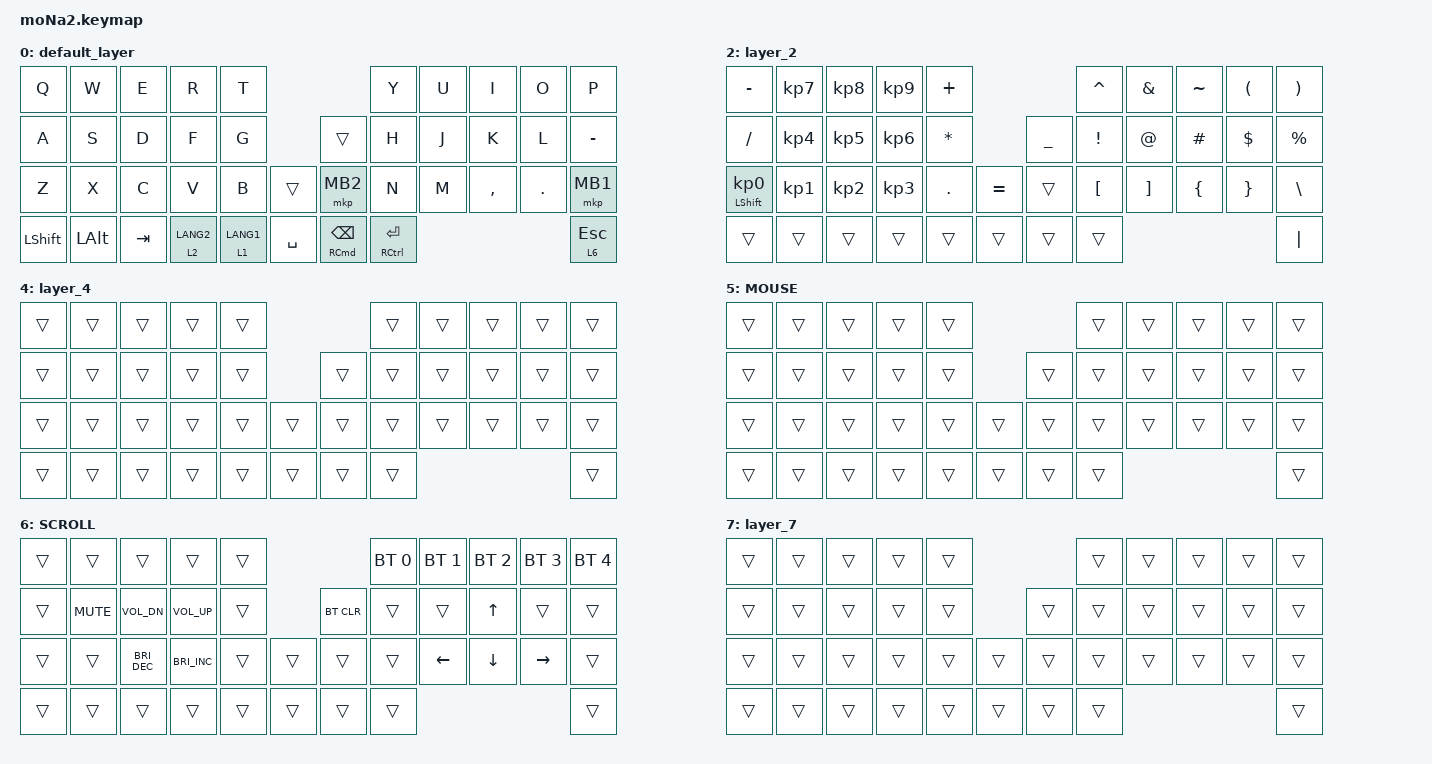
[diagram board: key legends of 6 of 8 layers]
#include <behaviors.dtsi>
#include <dt-bindings/zmk/bt.h>
#include <dt-bindings/zmk/keys.h>
#include <dt-bindings/zmk/pointing.h>

#define ZMK_POINTING_DEFAULT_SCRL_VAL 100
#define MOUSE 5
#define SCROLL 6

&mt {
    flavor = "balanced";
    quick-tap-ms = <0>;
};

/ {
    combos {
        compatible = "zmk,combos";

        combo_right_click {
            bindings = <&mkp MB2>;
            key-positions = <32 41>;
        };
    };

    macros {
        to_layer_0: to_layer_0 {
            compatible = "zmk,behavior-macro-one-param";
            #binding-cells = <1>;
            bindings = <&to 0 &macro_param_1to1 &kp MACRO_PLACEHOLDER>;
            label = "TO_LAYER_0";
        };

    };

    behaviors {
        lt_to_layer_0: lt_to_layer_0 {
            compatible = "zmk,behavior-hold-tap";
            label = "LAYER_TAP_TO_0";
            bindings = <&mo>, <&to_layer_0>;

            #binding-cells = <2>;
            tapping-term-ms = <200>;
        };

        /* [変更点1] スクロール方向を反転 */

        scroll_up_down: scroll_up_down {
            compatible = "zmk,behavior-sensor-rotate";
            #sensor-binding-cells = <0>;
            bindings = <&msc SCRL_UP>, <&msc SCRL_DOWN>;

            tap-ms = <20>;
            label = "scroll_up_down";
        };

        volume: volume {
            compatible = "zmk,behavior-sensor-rotate";
            label = "VOLUME";
            #sensor-binding-cells = <0>;
            bindings = <&kp C_VOLUME_DOWN>, <&kp C_VOLUME_UP>;
        };

        mt_qk: mt_quick_tap {
            compatible = "zmk,behavior-hold-tap";
            label = "MOD_TAP_QUICK_TAP";
            #binding-cells = <2>;
            tapping-term-ms = <200>;
            flavor = "balanced";
            quick-tap-ms = <200>;
            bindings = <&kp>, <&kp>;
        };
    };

    keymap {
        compatible = "zmk,keymap";

        /*
         * キーポジション名:
         *
         * L1_1  L1_2  L1_3  L1_4  L1_5                        R1_1  R1_2  R1_3  R1_4  R1_5
         * L2_1  L2_2  L2_3  L2_4  L2_5              R2_1      R2_2  R2_3  R2_4  R2_5  R2_6
         * L3_1  L3_2  L3_3  L3_4  L3_5  L3_6        R3_1      R3_2  R3_3  R3_4  R3_5  R3_6
         * L4_1  L4_2  L4_3  L4_4  L4_5  L4_6        R4_1      R4_2                    R4_3
         *
         * トラックボール: pointing device (中央)
         * ロータリーエンコーダ: sensor-bindings で定義
         */

        default_layer {
            bindings = <
&kp Q           &kp W         &kp E    &kp R        &kp T                                                     &kp Y                    &kp U  &kp I      &kp O       &kp P
&kp A           &kp S         &kp D    &kp F        &kp G                     &trans                          &kp H                    &kp J  &kp K      &kp L       &kp MINUS
&kp Z           &kp X         &kp C    &kp V        &kp B        &trans       &mkp MB2                        &kp N                    &kp M  &kp COMMA  &kp PERIOD  &mkp MB1
&kp LEFT_SHIFT  &kp LEFT_ALT  &kp TAB  &lt 2 LANG2  &lt 1 LANG1  &kp SPACE    &mt_qk RIGHT_COMMAND BACKSPACE  &mt RIGHT_CONTROL ENTER                                &lt 6 ESC
            >;

            sensor-bindings = <&scroll_up_down>;
        };

        layer_1 {
            bindings = <
&trans  &kp NUMBER_1  &kp NUMBER_2  &kp NUMBER_3  &trans                    &trans         &kp MINUS          &kp PLUS   &kp PIPE           &kp TILDE
&trans  &kp NUMBER_4  &kp NUMBER_5  &kp NUMBER_6  &trans            &trans  &kp LBKT       &kp RIGHT_BRACKET  &kp COLON  &kp DOUBLE_QUOTES  &kp MINUS
&trans  &kp N7        &kp N8        &kp N9        &kp N0  &trans    &trans  &kp LESS_THAN  &kp GREATER_THAN   &kp SLASH  &trans             &trans
&trans  &trans        &trans        &trans        &trans  &trans    &trans  &trans
            >;

            sensor-bindings = <&scroll_up_down>;
        };

        layer_2 {
            bindings = <
&kp MINUS                   &kp KP_NUMBER_7  &kp KP_NUMBER_8  &kp KP_NUMBER_9  &kp PLUS                                   &kp CARET         &kp AMPERSAND      &kp TILDE       &kp LEFT_PARENTHESIS  &kp RIGHT_PARENTHESIS
&kp SLASH                   &kp KP_NUMBER_4  &kp KP_NUMBER_5  &kp KP_NUMBER_6  &kp ASTERISK               &kp UNDERSCORE  &kp EXCLAMATION   &kp AT_SIGN        &kp HASH        &kp DOLLAR            &kp PERCENT
&mt LEFT_SHIFT KP_NUMBER_0  &kp KP_NUMBER_1  &kp KP_NUMBER_2  &kp KP_NUMBER_3  &kp PERIOD    &kp EQUAL    &trans          &kp LEFT_BRACKET  &kp RIGHT_BRACKET  &kp LEFT_BRACE  &kp RIGHT_BRACE       &kp BACKSLASH
&trans                      &trans           &trans           &trans           &trans        &trans       &trans          &trans                                                                     &kp PIPE
            >;

            sensor-bindings = <&scroll_up_down>;
        };

        layer_3 {
            bindings = <
&trans  &trans  &trans  &trans  &trans                    &trans  &trans  &trans  &trans  &trans
&trans  &trans  &trans  &trans  &trans            &trans  &trans  &trans  &trans  &trans  &trans
&trans  &trans  &trans  &trans  &trans  &trans    &trans  &trans  &trans  &trans  &trans  &trans
&trans  &trans  &trans  &trans  &trans  &trans    &trans  &trans
            >;

            sensor-bindings = <&volume>;
        };

        layer_4 {
            bindings = <
&trans  &trans  &trans  &trans  &trans                    &trans  &trans  &trans  &trans  &trans
&trans  &trans  &trans  &trans  &trans            &trans  &trans  &trans  &trans  &trans  &trans
&trans  &trans  &trans  &trans  &trans  &trans    &trans  &trans  &trans  &trans  &trans  &trans
&trans  &trans  &trans  &trans  &trans  &trans    &trans  &trans                          &trans
            >;

            sensor-bindings = <&scroll_up_down>;
        };

        MOUSE {
            bindings = <
&trans  &trans  &trans  &trans  &trans                    &trans  &trans  &trans  &trans  &trans
&trans  &trans  &trans  &trans  &trans            &trans  &trans  &trans  &trans  &trans  &trans
&trans  &trans  &trans  &trans  &trans  &trans    &trans  &trans  &trans  &trans  &trans  &trans
&trans  &trans  &trans  &trans  &trans  &trans    &trans  &trans                          &trans
            >;

            sensor-bindings = <&scroll_up_down>;
        };

        SCROLL {
            bindings = <
&trans  &trans      &trans                &trans                &trans                        &bt BT_SEL 0  &bt BT_SEL 1    &bt BT_SEL 2    &bt BT_SEL 3     &bt BT_SEL 4
&trans  &kp C_MUTE  &kp C_VOL_DN          &kp C_VOL_UP          &trans            &bt BT_CLR  &trans        &trans          &kp UP_ARROW    &trans           &trans
&trans  &trans      &kp C_BRIGHTNESS_DEC  &kp C_BRIGHTNESS_INC  &trans  &trans    &trans      &trans        &kp LEFT_ARROW  &kp DOWN_ARROW  &kp RIGHT_ARROW  &trans
&trans  &trans      &trans                &trans                &trans  &trans    &trans      &trans                                                         &trans
            >;

            sensor-bindings = <&volume>;
        };

        layer_7 {
            bindings = <
&trans  &trans  &trans  &trans  &trans                    &trans  &trans  &trans  &trans  &trans
&trans  &trans  &trans  &trans  &trans            &trans  &trans  &trans  &trans  &trans  &trans
&trans  &trans  &trans  &trans  &trans  &trans    &trans  &trans  &trans  &trans  &trans  &trans
&trans  &trans  &trans  &trans  &trans  &trans    &trans  &trans                          &trans
            >;
        };
    };
};
